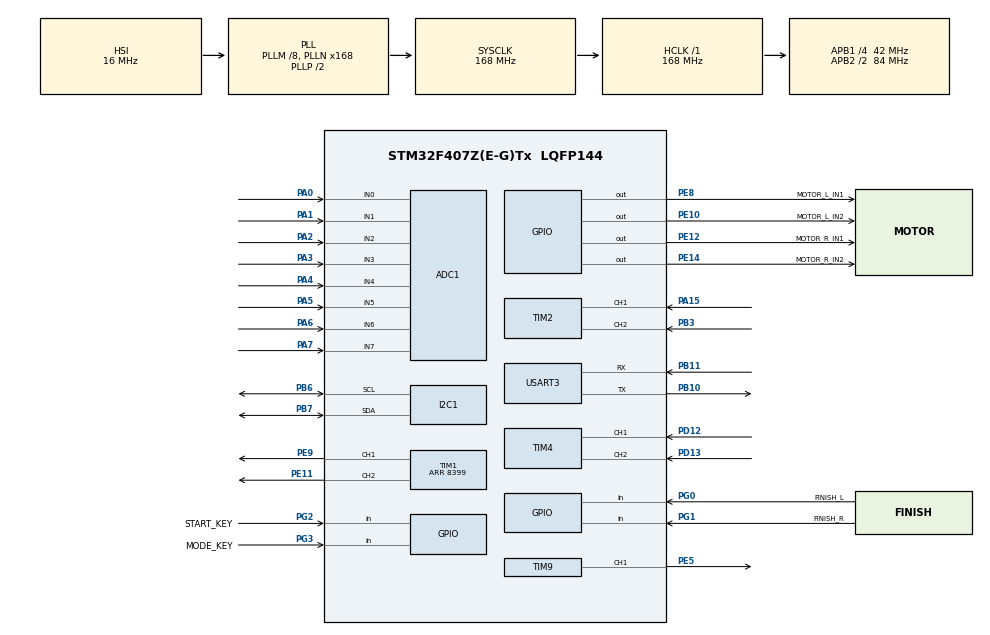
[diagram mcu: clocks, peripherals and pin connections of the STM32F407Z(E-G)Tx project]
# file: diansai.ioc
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ADC1.Channel-0\#ChannelRegularConversion=ADC_CHANNEL_0
ADC1.Channel-1\#ChannelRegularConversion=ADC_CHANNEL_1
ADC1.Channel-2\#ChannelRegularConversion=ADC_CHANNEL_2
ADC1.Channel-3\#ChannelRegularConversion=ADC_CHANNEL_3
ADC1.Channel-4\#ChannelRegularConversion=ADC_CHANNEL_4
ADC1.Channel-5\#ChannelRegularConversion=ADC_CHANNEL_5
ADC1.Channel-6\#ChannelRegularConversion=ADC_CHANNEL_6
ADC1.Channel-7\#ChannelRegularConversion=ADC_CHANNEL_7
ADC1.DMAContinuousRequests=ENABLE
ADC1.EOCSelection=ADC_EOC_SEQ_CONV
ADC1.ExternalTrigConv=ADC_EXTERNALTRIGCONV_T8_TRGO
ADC1.ExternalTrigConvEdge=ADC_EXTERNALTRIGCONVEDGE_RISING
ADC1.NbrOfConversionFlag=1
ADC1.Rank-0\#ChannelRegularConversion=1
ADC1.Rank-1\#ChannelRegularConversion=2
ADC1.Rank-2\#ChannelRegularConversion=3
ADC1.Rank-3\#ChannelRegularConversion=4
ADC1.Rank-4\#ChannelRegularConversion=5
ADC1.Rank-5\#ChannelRegularConversion=6
ADC1.Rank-6\#ChannelRegularConversion=7
ADC1.Rank-7\#ChannelRegularConversion=8
ADC1.SamplingTime-0\#ChannelRegularConversion=ADC_SAMPLETIME_84CYCLES
ADC1.SamplingTime-1\#ChannelRegularConversion=ADC_SAMPLETIME_84CYCLES
ADC1.SamplingTime-2\#ChannelRegularConversion=ADC_SAMPLETIME_84CYCLES
ADC1.SamplingTime-3\#ChannelRegularConversion=ADC_SAMPLETIME_84CYCLES
ADC1.SamplingTime-4\#ChannelRegularConversion=ADC_SAMPLETIME_84CYCLES
ADC1.SamplingTime-5\#ChannelRegularConversion=ADC_SAMPLETIME_84CYCLES
ADC1.SamplingTime-6\#ChannelRegularConversion=ADC_SAMPLETIME_84CYCLES
ADC1.SamplingTime-7\#ChannelRegularConversion=ADC_SAMPLETIME_84CYCLES
ADC1.ScanConvMode=ENABLE
ADC1.master=1
Dma.ADC1.0.Direction=DMA_PERIPH_TO_MEMORY
Dma.ADC1.0.FIFOMode=DMA_FIFOMODE_DISABLE
Dma.ADC1.0.Instance=DMA2_Stream0
Dma.ADC1.0.MemDataAlignment=DMA_MDATAALIGN_HALFWORD
Dma.ADC1.0.MemInc=DMA_MINC_ENABLE
Dma.ADC1.0.Mode=DMA_CIRCULAR
Dma.ADC1.0.PeriphDataAlignment=DMA_PDATAALIGN_HALFWORD
Dma.ADC1.0.PeriphInc=DMA_PINC_DISABLE
Dma.ADC1.0.Priority=DMA_PRIORITY_LOW
Dma.Request0=ADC1
Mcu.Family=STM32F4
Mcu.Name=STM32F407Z(E-G)Tx
Mcu.Package=LQFP144
NVIC.DMA2_Stream0_IRQn=true\:0\:0\:false\:false\:true\:false\:true\:true
NVIC.PriorityGroup=NVIC_PRIORITYGROUP_4
NVIC.USART3_IRQn=true\:1\:0\:false\:false\:true\:true\:true\:true
PA0-WKUP.Signal=ADCx_IN0
PA1.Signal=ADCx_IN1
PA13.Mode=Serial_Wire
PA13.Signal=SYS_JTMS-SWDIO
PA14.Mode=Serial_Wire
PA14.Signal=SYS_JTCK-SWCLK
PA15.Signal=S_TIM2_CH1_ETR
PA2.Signal=ADCx_IN2
PA3.Signal=ADCx_IN3
PA4.Signal=ADCx_IN4
PA5.Signal=ADCx_IN5
PA6.Signal=ADCx_IN6
PA7.Signal=ADCx_IN7
PB10.Mode=Asynchronous
PB10.Signal=USART3_TX
PB11.Mode=Asynchronous
PB11.Signal=USART3_RX
PB3.Signal=S_TIM2_CH2
PB6.Mode=I2C
PB6.Signal=I2C1_SCL
PB7.Mode=I2C
PB7.Signal=I2C1_SDA
PD12.Signal=S_TIM4_CH1
PD13.Signal=S_TIM4_CH2
PE10.GPIO_Label=MOTOR_L_IN2
PE10.Signal=GPIO_Output
PE11.Signal=S_TIM1_CH2
PE12.GPIO_Label=MOTOR_R_IN1
PE12.Signal=GPIO_Output
PE14.GPIO_Label=MOTOR_R_IN2
PE14.Signal=GPIO_Output
PE5.Signal=S_TIM9_CH1
PE8.GPIO_Label=MOTOR_L_IN1
PE8.Signal=GPIO_Output
PE9.Signal=S_TIM1_CH1
PG0.GPIO_Label=FINISH_L
PG0.GPIO_PuPd=GPIO_PULLUP
PG0.Signal=GPIO_Input
PG1.GPIO_Label=FINISH_R
PG1.GPIO_PuPd=GPIO_PULLUP
PG1.Signal=GPIO_Input
PG2.GPIO_Label=START_KEY
PG2.GPIO_PuPd=GPIO_PULLUP
PG2.Signal=GPIO_Input
PG3.GPIO_Label=MODE_KEY
PG3.GPIO_PuPd=GPIO_PULLUP
PG3.Signal=GPIO_Input
PH0-OSC_IN.Mode=HSE-External-Oscillator
PH0-OSC_IN.Signal=RCC_OSC_IN
PH1-OSC_OUT.Mode=HSE-External-Oscillator
PH1-OSC_OUT.Signal=RCC_OSC_OUT
ProjectManager.HeapSize=0x200
ProjectManager.StackSize=0x400
ProjectManager.TargetToolchain=MDK-ARM V5.32
RCC.48MHZClocksFreq_Value=84000000
RCC.AHBFreq_Value=168000000
RCC.APB1CLKDivider=RCC_HCLK_DIV4
RCC.APB1Freq_Value=42000000
RCC.APB1TimFreq_Value=84000000
RCC.APB2CLKDivider=RCC_HCLK_DIV2
RCC.APB2Freq_Value=84000000
RCC.APB2TimFreq_Value=168000000
RCC.CortexFreq_Value=168000000
RCC.HCLKFreq_Value=168000000
RCC.HSE_VALUE=25000000
RCC.HSI_VALUE=16000000
RCC.LSE_VALUE=32768
RCC.PLLM=8
RCC.PLLN=168
RCC.SYSCLKFreq_VALUE=168000000
RCC.SYSCLKSource=RCC_SYSCLKSOURCE_PLLCLK
RCC.VCOOutputFreq_Value=336000000
SH.ADCx_IN0.0=ADC1_IN0,IN0
SH.ADCx_IN1.0=ADC1_IN1,IN1
SH.ADCx_IN2.0=ADC1_IN2,IN2
SH.ADCx_IN3.0=ADC1_IN3,IN3
SH.ADCx_IN4.0=ADC1_IN4,IN4
SH.ADCx_IN5.0=ADC1_IN5,IN5
SH.ADCx_IN6.0=ADC1_IN6,IN6
SH.ADCx_IN7.0=ADC1_IN7,IN7
SH.S_TIM1_CH1.0=TIM1_CH1,PWM Generation1 CH1
SH.S_TIM1_CH2.0=TIM1_CH2,PWM Generation2 CH2
SH.S_TIM2_CH1_ETR.0=TIM2_CH1,Encoder_Interface
SH.S_TIM2_CH2.0=TIM2_CH2,Encoder_Interface
SH.S_TIM4_CH1.0=TIM4_CH1,Encoder_Interface
SH.S_TIM4_CH2.0=TIM4_CH2,Encoder_Interface
SH.S_TIM9_CH1.0=TIM9_CH1,PWM Generation1 CH1
TIM1.Channel-PWM\ Generation1\ CH1=TIM_CHANNEL_1
TIM1.Channel-PWM\ Generation2\ CH2=TIM_CHANNEL_2
TIM1.Period=8399
TIM2.EncoderMode=TIM_ENCODERMODE_TI12
TIM2.IC1Filter=4
TIM2.IC2Filter=4
TIM4.EncoderMode=TIM_ENCODERMODE_TI12
TIM4.IC1Filter=4
TIM4.IC2Filter=4
TIM8.MasterOutputTrigger=TIM_TRGO_UPDATE
TIM8.Period=999
TIM8.Prescaler=167
TIM9.Channel-PWM\ Generation1\ CH1=TIM_CHANNEL_1
USART3.VirtualMode=VM_ASYNC
VP_TIM8_VS_ClockSourceINT.Mode=Internal
board=custom

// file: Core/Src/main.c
/* USER CODE BEGIN Header */
/**
  ******************************************************************************
  * @file           : main.c
  * @brief          : Main program body
  ******************************************************************************
  * @attention
  *
  * Copyright (c) 2026 STMicroelectronics.
  * All rights reserved.
  *
  * This software is licensed under terms that can be found in the LICENSE file
  * in the root directory of this software component.
  * If no LICENSE file comes with this software, it is provided AS-IS.
  *
  ******************************************************************************
  */
/* USER CODE END Header */
#include "main.h"

/* USER CODE BEGIN Includes */
#include "app.h"

/* USER CODE END Includes */

ADC_HandleTypeDef hadc1;
DMA_HandleTypeDef hdma_adc1;

I2C_HandleTypeDef hi2c1;

TIM_HandleTypeDef htim1;
TIM_HandleTypeDef htim2;
TIM_HandleTypeDef htim4;
TIM_HandleTypeDef htim8;
TIM_HandleTypeDef htim9;

UART_HandleTypeDef huart3;

void SystemClock_Config(void);
static void MX_GPIO_Init(void);
static void MX_DMA_Init(void);
static void MX_ADC1_Init(void);
static void MX_I2C1_Init(void);
static void MX_TIM1_Init(void);
static void MX_TIM2_Init(void);
static void MX_TIM4_Init(void);
static void MX_TIM8_Init(void);
static void MX_TIM9_Init(void);
static void MX_USART3_UART_Init(void);

int main(void)
{

  /* MCU Configuration--------------------------------------------------------*/

  /* Reset of all peripherals, Initializes the Flash interface and the Systick. */
  HAL_Init();

  /* Configure the system clock */
  SystemClock_Config();

  /* Initialize all configured peripherals */
  MX_GPIO_Init();
  MX_DMA_Init();
  MX_ADC1_Init();
  MX_I2C1_Init();
  MX_TIM1_Init();
  MX_TIM2_Init();
  MX_TIM4_Init();
  MX_TIM8_Init();
  MX_TIM9_Init();
  MX_USART3_UART_Init();
  /* USER CODE BEGIN 2 */

  if (App_Init(&hadc1, &htim8, &htim1, &htim2, &htim4,
               &hi2c1, &huart3) != HAL_OK)
  {
    Error_Handler();
  }

  /* USER CODE END 2 */

  /* Infinite loop */
  /* USER CODE BEGIN WHILE */
  while (1)
  {
    App_Run();
    /* USER CODE END WHILE */

  }
}

void SystemClock_Config(void)
{
  RCC_OscInitTypeDef RCC_OscInitStruct = {0};
  RCC_ClkInitTypeDef RCC_ClkInitStruct = {0};

  /** Configure the main internal regulator output voltage
  */
  __HAL_RCC_PWR_CLK_ENABLE();
  __HAL_PWR_VOLTAGESCALING_CONFIG(PWR_REGULATOR_VOLTAGE_SCALE1);

  /** Initializes the RCC Oscillators according to the specified parameters
  * in the RCC_OscInitTypeDef structure.
  */
  RCC_OscInitStruct.OscillatorType = RCC_OSCILLATORTYPE_HSI;
  RCC_OscInitStruct.HSIState = RCC_HSI_ON;
  RCC_OscInitStruct.HSICalibrationValue = RCC_HSICALIBRATION_DEFAULT;
  RCC_OscInitStruct.PLL.PLLState = RCC_PLL_ON;
  RCC_OscInitStruct.PLL.PLLSource = RCC_PLLSOURCE_HSI;
  RCC_OscInitStruct.PLL.PLLM = 8;
  RCC_OscInitStruct.PLL.PLLN = 168;
  RCC_OscInitStruct.PLL.PLLP = RCC_PLLP_DIV2;
  RCC_OscInitStruct.PLL.PLLQ = 4;
  if (HAL_RCC_OscConfig(&RCC_OscInitStruct) != HAL_OK)
  {
    Error_Handler();
  }

  /** Initializes the CPU, AHB and APB buses clocks
  */
  RCC_ClkInitStruct.ClockType = RCC_CLOCKTYPE_HCLK|RCC_CLOCKTYPE_SYSCLK
                              |RCC_CLOCKTYPE_PCLK1|RCC_CLOCKTYPE_PCLK2;
  RCC_ClkInitStruct.SYSCLKSource = RCC_SYSCLKSOURCE_PLLCLK;
  RCC_ClkInitStruct.AHBCLKDivider = RCC_SYSCLK_DIV1;
  RCC_ClkInitStruct.APB1CLKDivider = RCC_HCLK_DIV4;
  RCC_ClkInitStruct.APB2CLKDivider = RCC_HCLK_DIV2;

  if (HAL_RCC_ClockConfig(&RCC_ClkInitStruct, FLASH_LATENCY_5) != HAL_OK)
  {
    Error_Handler();
  }
}

static void MX_ADC1_Init(void)
{

  ADC_ChannelConfTypeDef sConfig = {0};

  /** Configure the global features of the ADC (Clock, Resolution, Data Alignment and number of conversion)
  */
  hadc1.Instance = ADC1;
  hadc1.Init.ClockPrescaler = ADC_CLOCK_SYNC_PCLK_DIV4;
  hadc1.Init.Resolution = ADC_RESOLUTION_12B;
  hadc1.Init.ScanConvMode = ENABLE;
  hadc1.Init.ContinuousConvMode = DISABLE;
  hadc1.Init.DiscontinuousConvMode = DISABLE;
  hadc1.Init.ExternalTrigConvEdge = ADC_EXTERNALTRIGCONVEDGE_RISING;
  hadc1.Init.ExternalTrigConv = ADC_EXTERNALTRIGCONV_T8_TRGO;
  hadc1.Init.DataAlign = ADC_DATAALIGN_RIGHT;
  hadc1.Init.NbrOfConversion = 8;
  hadc1.Init.DMAContinuousRequests = ENABLE;
  hadc1.Init.EOCSelection = ADC_EOC_SEQ_CONV;
  if (HAL_ADC_Init(&hadc1) != HAL_OK)
  {
    Error_Handler();
  }

  /** Configure for the selected ADC regular channel its corresponding rank in the sequencer and its sample time.
  */
  sConfig.Channel = ADC_CHANNEL_0;
  sConfig.Rank = 1;
  sConfig.SamplingTime = ADC_SAMPLETIME_84CYCLES;
  if (HAL_ADC_ConfigChannel(&hadc1, &sConfig) != HAL_OK)
  {
    Error_Handler();
  }

  sConfig.Channel = ADC_CHANNEL_1;
  sConfig.Rank = 2;
  if (HAL_ADC_ConfigChannel(&hadc1, &sConfig) != HAL_OK)
  {
    Error_Handler();
  }

  sConfig.Channel = ADC_CHANNEL_2;
  sConfig.Rank = 3;
  if (HAL_ADC_ConfigChannel(&hadc1, &sConfig) != HAL_OK)
  {
    Error_Handler();
  }

  sConfig.Channel = ADC_CHANNEL_3;
  sConfig.Rank = 4;
  if (HAL_ADC_ConfigChannel(&hadc1, &sConfig) != HAL_OK)
  {
    Error_Handler();
  }

  sConfig.Channel = ADC_CHANNEL_4;
  sConfig.Rank = 5;
  if (HAL_ADC_ConfigChannel(&hadc1, &sConfig) != HAL_OK)
  {
    Error_Handler();
  }

  sConfig.Channel = ADC_CHANNEL_5;
  sConfig.Rank = 6;
  if (HAL_ADC_ConfigChannel(&hadc1, &sConfig) != HAL_OK)
  {
    Error_Handler();
  }

  sConfig.Channel = ADC_CHANNEL_6;
  sConfig.Rank = 7;
  if (HAL_ADC_ConfigChannel(&hadc1, &sConfig) != HAL_OK)
  {
    Error_Handler();
  }

  sConfig.Channel = ADC_CHANNEL_7;
  sConfig.Rank = 8;
  if (HAL_ADC_ConfigChannel(&hadc1, &sConfig) != HAL_OK)
  {
    Error_Handler();
  }

}

static void MX_I2C1_Init(void)
{

  hi2c1.Instance = I2C1;
  hi2c1.Init.ClockSpeed = 100000;
  hi2c1.Init.DutyCycle = I2C_DUTYCYCLE_2;
  hi2c1.Init.OwnAddress1 = 0;
  hi2c1.Init.AddressingMode = I2C_ADDRESSINGMODE_7BIT;
  hi2c1.Init.DualAddressMode = I2C_DUALADDRESS_DISABLE;
  hi2c1.Init.OwnAddress2 = 0;
  hi2c1.Init.GeneralCallMode = I2C_GENERALCALL_DISABLE;
  hi2c1.Init.NoStretchMode = I2C_NOSTRETCH_DISABLE;
  if (HAL_I2C_Init(&hi2c1) != HAL_OK)
  {
    Error_Handler();
  }

}

static void MX_TIM1_Init(void)
{

  TIM_MasterConfigTypeDef sMasterConfig = {0};
  TIM_OC_InitTypeDef sConfigOC = {0};
  TIM_BreakDeadTimeConfigTypeDef sBreakDeadTimeConfig = {0};

  htim1.Instance = TIM1;
  htim1.Init.Prescaler = 0;
  htim1.Init.CounterMode = TIM_COUNTERMODE_UP;
  htim1.Init.Period = 8399;
  htim1.Init.ClockDivision = TIM_CLOCKDIVISION_DIV1;
  htim1.Init.RepetitionCounter = 0;
  htim1.Init.AutoReloadPreload = TIM_AUTORELOAD_PRELOAD_DISABLE;
  if (HAL_TIM_PWM_Init(&htim1) != HAL_OK)
  {
    Error_Handler();
  }
  sMasterConfig.MasterOutputTrigger = TIM_TRGO_RESET;
  sMasterConfig.MasterSlaveMode = TIM_MASTERSLAVEMODE_DISABLE;
  if (HAL_TIMEx_MasterConfigSynchronization(&htim1, &sMasterConfig) != HAL_OK)
  {
    Error_Handler();
  }
  sConfigOC.OCMode = TIM_OCMODE_PWM1;
  sConfigOC.Pulse = 0;
  sConfigOC.OCPolarity = TIM_OCPOLARITY_HIGH;
  sConfigOC.OCNPolarity = TIM_OCNPOLARITY_HIGH;
  sConfigOC.OCFastMode = TIM_OCFAST_DISABLE;
  sConfigOC.OCIdleState = TIM_OCIDLESTATE_RESET;
  sConfigOC.OCNIdleState = TIM_OCNIDLESTATE_RESET;
  if (HAL_TIM_PWM_ConfigChannel(&htim1, &sConfigOC, TIM_CHANNEL_1) != HAL_OK)
  {
    Error_Handler();
  }
  if (HAL_TIM_PWM_ConfigChannel(&htim1, &sConfigOC, TIM_CHANNEL_2) != HAL_OK)
  {
    Error_Handler();
  }
  sBreakDeadTimeConfig.OffStateRunMode = TIM_OSSR_DISABLE;
  sBreakDeadTimeConfig.OffStateIDLEMode = TIM_OSSI_DISABLE;
  sBreakDeadTimeConfig.LockLevel = TIM_LOCKLEVEL_OFF;
  sBreakDeadTimeConfig.DeadTime = 0;
  sBreakDeadTimeConfig.BreakState = TIM_BREAK_DISABLE;
  sBreakDeadTimeConfig.BreakPolarity = TIM_BREAKPOLARITY_HIGH;
  sBreakDeadTimeConfig.AutomaticOutput = TIM_AUTOMATICOUTPUT_DISABLE;
  if (HAL_TIMEx_ConfigBreakDeadTime(&htim1, &sBreakDeadTimeConfig) != HAL_OK)
  {
    Error_Handler();
  }
  HAL_TIM_MspPostInit(&htim1);

}

static void MX_TIM2_Init(void)
{

  TIM_Encoder_InitTypeDef sConfig = {0};
  TIM_MasterConfigTypeDef sMasterConfig = {0};

  htim2.Instance = TIM2;
  htim2.Init.Prescaler = 0;
  htim2.Init.CounterMode = TIM_COUNTERMODE_UP;
  htim2.Init.Period = 4294967295;
  htim2.Init.ClockDivision = TIM_CLOCKDIVISION_DIV1;
  htim2.Init.AutoReloadPreload = TIM_AUTORELOAD_PRELOAD_DISABLE;
  sConfig.EncoderMode = TIM_ENCODERMODE_TI12;
  sConfig.IC1Polarity = TIM_ICPOLARITY_RISING;
  sConfig.IC1Selection = TIM_ICSELECTION_DIRECTTI;
  sConfig.IC1Prescaler = TIM_ICPSC_DIV1;
  sConfig.IC1Filter = 4;
  sConfig.IC2Polarity = TIM_ICPOLARITY_RISING;
  sConfig.IC2Selection = TIM_ICSELECTION_DIRECTTI;
  sConfig.IC2Prescaler = TIM_ICPSC_DIV1;
  sConfig.IC2Filter = 4;
  if (HAL_TIM_Encoder_Init(&htim2, &sConfig) != HAL_OK)
  {
    Error_Handler();
  }
  sMasterConfig.MasterOutputTrigger = TIM_TRGO_RESET;
  sMasterConfig.MasterSlaveMode = TIM_MASTERSLAVEMODE_DISABLE;
  if (HAL_TIMEx_MasterConfigSynchronization(&htim2, &sMasterConfig) != HAL_OK)
  {
    Error_Handler();
  }

}

static void MX_TIM4_Init(void)
{

  TIM_Encoder_InitTypeDef sConfig = {0};
  TIM_MasterConfigTypeDef sMasterConfig = {0};

  htim4.Instance = TIM4;
  htim4.Init.Prescaler = 0;
  htim4.Init.CounterMode = TIM_COUNTERMODE_UP;
  htim4.Init.Period = 65535;
  htim4.Init.ClockDivision = TIM_CLOCKDIVISION_DIV1;
  htim4.Init.AutoReloadPreload = TIM_AUTORELOAD_PRELOAD_DISABLE;
  sConfig.EncoderMode = TIM_ENCODERMODE_TI12;
  sConfig.IC1Polarity = TIM_ICPOLARITY_RISING;
  sConfig.IC1Selection = TIM_ICSELECTION_DIRECTTI;
  sConfig.IC1Prescaler = TIM_ICPSC_DIV1;
  sConfig.IC1Filter = 4;
  sConfig.IC2Polarity = TIM_ICPOLARITY_RISING;
  sConfig.IC2Selection = TIM_ICSELECTION_DIRECTTI;
  sConfig.IC2Prescaler = TIM_ICPSC_DIV1;
  sConfig.IC2Filter = 4;
  if (HAL_TIM_Encoder_Init(&htim4, &sConfig) != HAL_OK)
  {
    Error_Handler();
  }
  sMasterConfig.MasterOutputTrigger = TIM_TRGO_RESET;
  sMasterConfig.MasterSlaveMode = TIM_MASTERSLAVEMODE_DISABLE;
  if (HAL_TIMEx_MasterConfigSynchronization(&htim4, &sMasterConfig) != HAL_OK)
  {
    Error_Handler();
  }

}

static void MX_TIM8_Init(void)
{

  TIM_ClockConfigTypeDef sClockSourceConfig = {0};
  TIM_MasterConfigTypeDef sMasterConfig = {0};

  /* USER CODE BEGIN TIM8_Init 1 */
  __HAL_RCC_TIM8_CLK_ENABLE();
  /* USER CODE END TIM8_Init 1 */
  htim8.Instance = TIM8;
  htim8.Init.Prescaler = 167;
  htim8.Init.CounterMode = TIM_COUNTERMODE_UP;
  htim8.Init.Period = 999;
  htim8.Init.ClockDivision = TIM_CLOCKDIVISION_DIV1;
  htim8.Init.RepetitionCounter = 0;
  htim8.Init.AutoReloadPreload = TIM_AUTORELOAD_PRELOAD_DISABLE;
  if (HAL_TIM_Base_Init(&htim8) != HAL_OK)
  {
    Error_Handler();
  }
  sClockSourceConfig.ClockSource = TIM_CLOCKSOURCE_INTERNAL;
  if (HAL_TIM_ConfigClockSource(&htim8, &sClockSourceConfig) != HAL_OK)
  {
    Error_Handler();
  }
  sMasterConfig.MasterOutputTrigger = TIM_TRGO_UPDATE;
  sMasterConfig.MasterSlaveMode = TIM_MASTERSLAVEMODE_DISABLE;
  if (HAL_TIMEx_MasterConfigSynchronization(&htim8, &sMasterConfig) != HAL_OK)
  {
    Error_Handler();
  }

}

static void MX_TIM9_Init(void)
{

  TIM_OC_InitTypeDef sConfigOC = {0};

  htim9.Instance = TIM9;
  htim9.Init.Prescaler = 0;
  htim9.Init.CounterMode = TIM_COUNTERMODE_UP;
  htim9.Init.Period = 65535;
  htim9.Init.ClockDivision = TIM_CLOCKDIVISION_DIV1;
  htim9.Init.AutoReloadPreload = TIM_AUTORELOAD_PRELOAD_DISABLE;
  if (HAL_TIM_PWM_Init(&htim9) != HAL_OK)
  {
    Error_Handler();
  }
  sConfigOC.OCMode = TIM_OCMODE_PWM1;
  sConfigOC.Pulse = 0;
  sConfigOC.OCPolarity = TIM_OCPOLARITY_HIGH;
  sConfigOC.OCFastMode = TIM_OCFAST_DISABLE;
  if (HAL_TIM_PWM_ConfigChannel(&htim9, &sConfigOC, TIM_CHANNEL_1) != HAL_OK)
  {
    Error_Handler();
  }
  HAL_TIM_MspPostInit(&htim9);

}

static void MX_USART3_UART_Init(void)
{

  huart3.Instance = USART3;
  huart3.Init.BaudRate = 115200;
  huart3.Init.WordLength = UART_WORDLENGTH_8B;
  huart3.Init.StopBits = UART_STOPBITS_1;
  huart3.Init.Parity = UART_PARITY_NONE;
  huart3.Init.Mode = UART_MODE_TX_RX;
  huart3.Init.HwFlowCtl = UART_HWCONTROL_NONE;
  huart3.Init.OverSampling = UART_OVERSAMPLING_16;
  if (HAL_UART_Init(&huart3) != HAL_OK)
  {
    Error_Handler();
  }

}

static void MX_DMA_Init(void)
{

  /* DMA controller clock enable */
  __HAL_RCC_DMA2_CLK_ENABLE();

  /* DMA interrupt init */
  /* DMA2_Stream0_IRQn interrupt configuration */
  HAL_NVIC_SetPriority(DMA2_Stream0_IRQn, 0, 0);
  HAL_NVIC_EnableIRQ(DMA2_Stream0_IRQn);

}

static void MX_GPIO_Init(void)
{
  GPIO_InitTypeDef GPIO_InitStruct = {0};

  /* GPIO Ports Clock Enable */
  __HAL_RCC_GPIOE_CLK_ENABLE();
  __HAL_RCC_GPIOH_CLK_ENABLE();
  __HAL_RCC_GPIOA_CLK_ENABLE();
  __HAL_RCC_GPIOB_CLK_ENABLE();
  __HAL_RCC_GPIOD_CLK_ENABLE();
  __HAL_RCC_GPIOG_CLK_ENABLE();

  HAL_GPIO_WritePin(GPIOE, MOTOR_L_IN1_Pin|MOTOR_L_IN2_Pin
                          |MOTOR_R_IN1_Pin|MOTOR_R_IN2_Pin, GPIO_PIN_RESET);

  GPIO_InitStruct.Pin = MOTOR_L_IN1_Pin|MOTOR_L_IN2_Pin
                        |MOTOR_R_IN1_Pin|MOTOR_R_IN2_Pin;
  GPIO_InitStruct.Mode = GPIO_MODE_OUTPUT_PP;
  GPIO_InitStruct.Pull = GPIO_NOPULL;
  GPIO_InitStruct.Speed = GPIO_SPEED_FREQ_LOW;
  HAL_GPIO_Init(GPIOE, &GPIO_InitStruct);

  GPIO_InitStruct.Pin = FINISH_L_Pin|FINISH_R_Pin|START_KEY_Pin|MODE_KEY_Pin;
  GPIO_InitStruct.Mode = GPIO_MODE_INPUT;
  GPIO_InitStruct.Pull = GPIO_PULLUP;
  HAL_GPIO_Init(GPIOG, &GPIO_InitStruct);

}

void Error_Handler(void)
{
  __disable_irq();
  while (1)
  {
  }
}
